AUTOSAR XML (schema 00050)
package /VectorAutosarExplorerGeneratedObjects/SYSTEM
  system System
package /VectorAutosarExplorerGeneratedObjects/DriveTrain
  can cluster DriveTrain: baudrate=500000, protocol-name=CAN, speed=250000
    can physical channel CANChannel: comm-connectors=[Connector_HeadUnit_ECU_95c543f36301506f, Connector_Battery_ECU_9b296f217afdec45]
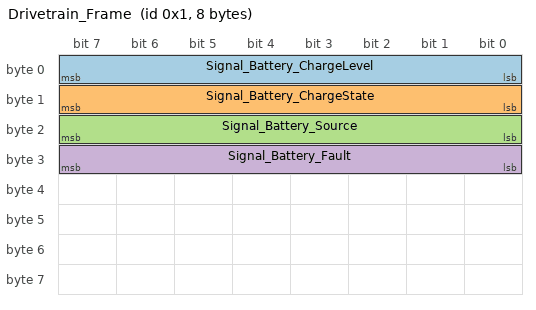
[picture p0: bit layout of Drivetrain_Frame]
      frame Drivetrain_Frame: id 0x1, from Battery_ECU, to HeadUnit_ECU, frame-length=8, can-addressing-mode=STANDARD, can-frame-tx-behavior=CAN-20
        pdu Drivetrain_Frame_PDU: length=8, transmission-mode-true-timing=cyclic-timing=time-period=1
          signal Signal_Battery_ChargeLevel: start 0, 8 bit, little-endian, system signal Signal_Battery_ChargeLevel_a9a9e6bb3df09836, data-type-policy=OVERRIDE, base-type=Temperature_BaseType, compu {phys=raw for raw 0..100; unit %}, to HeadUnit_ECU
          signal Signal_Battery_ChargeState: start 8, 8 bit, little-endian, system signal Signal_Battery_ChargeState_f9e63a8c0f39a04e, data-type-policy=OVERRIDE, base-type=Temperature_BaseType, compu {1=Charging, 2=Discharching (Discharging)}, to HeadUnit_ECU
          signal Signal_Battery_Source: start 16, 8 bit, little-endian, system signal Signal_Battery_Source_ac1e62a0b9f55c34, data-type-policy=OVERRIDE, base-type=Temperature_BaseType, compu {1=Power Source Available (Plugged), 2=Power Source Unavailable (Unplugged)}, transfer-property=TRIGGERED-ON-CHANGE, to HeadUnit_ECU
          signal Signal_Battery_Fault: start 24, 8 bit, little-endian, system signal Signal_Battery_Fault_d01f21cc3fdfd642, data-type-policy=OVERRIDE, base-type=Temperature_BaseType, compu {1=Faulty, 0=NormalOperation}, transfer-property=TRIGGERED-ON-CHANGE, to HeadUnit_ECU
package /VectorAutosarExplorerGeneratedObjects/Comfort
  can cluster Comfort: baudrate=500000, protocol-name=CAN, speed=250000
    can physical channel CANChannel
      comm-connectors:
        Connector_HeadUnit_ECU_2c2a28c65677685b
        Connector_Fan_ECU_fbc5880ce1a0cdea
        Connector_HeatPump_ECU_3a9462d6cf84e8d4
        Connector_Seat_ECU_c42df0ed14de8bdb
        Connector_SteeringWheel_ECU_2a26ad9393d8e118
        Comfort_Connector_Tester_65957222c6148118
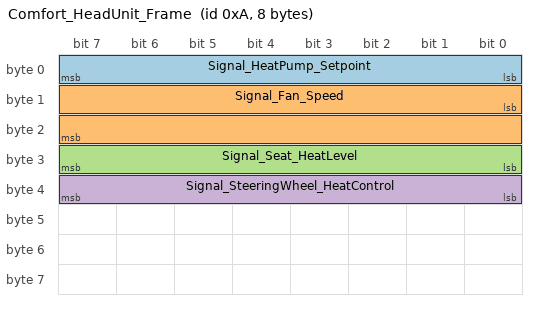
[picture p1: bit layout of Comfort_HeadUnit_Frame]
      frame Comfort_HeadUnit_Frame: id 0xA, from HeadUnit_ECU, to HeatPump_ECU Fan_ECU Seat_ECU SteeringWheel_ECU, frame-length=8, can-addressing-mode=STANDARD, can-frame-tx-behavior=CAN-20
        pdu Comfort_HeadUnit_Frame_PDU: length=8, transmission-mode-true-timing=cyclic-timing=time-period=0.1
          signal Signal_HeatPump_Setpoint: start 0, 8 bit, little-endian, system signal Signal_HeatPump_Setpoint_128f28339b77454b, data-type-policy=OVERRIDE, base-type=Temperature_BaseType, compu {phys=raw for raw 10..30; unit °C}, to HeatPump_ECU
          signal Signal_Fan_Speed: start 8, 16 bit, little-endian, system signal Signal_Fan_Setpoint_7226b1dfc825beac, data-type-policy=OVERRIDE, base-type=Speed_BaseType, compu {phys=raw for raw 0..3500; unit RPM}, to Fan_ECU
          signal Signal_Seat_HeatLevel: start 24, 8 bit, little-endian, system signal Signal_Seat_HeatLevel_70084504bb35d07f, data-type-policy=OVERRIDE, base-type=Temperature_BaseType, compu {0=Off, 1=Minimum (Low), 2=Medium, 3=Maximum (High)}, to Seat_ECU
          signal Signal_SteeringWheel_HeatControl: start 32, 8 bit, little-endian, system signal Signal_SteeringWheel_HeatControl_7a6769d229411a8c, data-type-policy=OVERRIDE, base-type=Temperature_BaseType, compu {1=Enabled (On), 0=Disabled (Off)}, to SteeringWheel_ECU
      frame Comfort_Fan_Frame: id 0x2, from Fan_ECU, to HeadUnit_ECU, frame-length=8, can-addressing-mode=STANDARD, can-frame-tx-behavior=CAN-20
        pdu Comfort_Fan_Frame_PDU: length=8, transmission-mode-true-timing=cyclic-timing=time-period=1
          signal Signal_Fan_Fault: start 0, 8 bit, little-endian, system signal Signal_Fan_Fault_f777c54e31a89d5c, data-type-policy=OVERRIDE, base-type=Temperature_BaseType, compu {1=Faulty, 0=NormalOperation}, transfer-property=TRIGGERED-ON-CHANGE, to HeadUnit_ECU
      frame Comfort_HeatPump_Frame: id 0x3, from HeatPump_ECU, to HeadUnit_ECU, frame-length=8, can-addressing-mode=STANDARD, can-frame-tx-behavior=CAN-20
        pdu Comfort_HeatPump_Frame_PDU: length=8, transmission-mode-true-timing=cyclic-timing=time-period=1
          signal Signal_HeatPump_Fault: start 0, 8 bit, little-endian, system signal sensor_frame_PDU_Fault_e8b584cee026b39c, data-type-policy=OVERRIDE, base-type=Temperature_BaseType, compu {1=Faulty, 0=NormalOperation}, transfer-property=TRIGGERED-ON-CHANGE, to HeadUnit_ECU
      frame Comfort_Seat_Frame: id 0x4, from Seat_ECU, to HeadUnit_ECU, frame-length=8, can-addressing-mode=STANDARD, can-frame-tx-behavior=CAN-20
        pdu Comfort_Seat_Frame_PDU: length=8, transmission-mode-true-timing=cyclic-timing=time-period=1
          signal Signal_Seat_Fault: start 0, 8 bit, little-endian, system signal Signal_Seat_Fault_d87a6a4f000a1433, data-type-policy=OVERRIDE, base-type=Temperature_BaseType, compu {1=Faulty, 0=NormalOperation}, transfer-property=TRIGGERED-ON-CHANGE, to HeadUnit_ECU
      frame Comfort_SteeringWheel_Frame: id 0x5, from SteeringWheel_ECU, to HeadUnit_ECU, frame-length=8, can-addressing-mode=STANDARD, can-frame-tx-behavior=CAN-20
        pdu Comfort_SteeringWheel_Frame_PDU: length=8, transmission-mode-true-timing=cyclic-timing=time-period=1
          signal Signal_SteeringWheel_Fault: start 0, 8 bit, little-endian, system signal Signal_SteeringWheel_Fault_45f4044b22d5124b, data-type-policy=OVERRIDE, base-type=Temperature_BaseType, compu {1=Faulty, 0=NormalOperation}, transfer-property=TRIGGERED-ON-CHANGE, to HeadUnit_ECU
      frame Comfort_Fan_NM_Tx: id 0x6, from Fan_ECU, frame-length=8, can-addressing-mode=STANDARD, can-frame-tx-behavior=CAN-20
        nm pdu Comfort_Fan_NM_PDU_Tx: length=8
      frame Comfort_Fan_NM_Rx: id 0x7, to Fan_ECU, frame-length=8, can-addressing-mode=STANDARD, can-frame-tx-behavior=CAN-20
        nm pdu Comfort_Fan_NM_PDU_Rx: length=8
      frame Comfort_TP_Diag_Request_Fan_ECU_Frame: id 0x1, from Tester, to Fan_ECU, frame-length=8, can-addressing-mode=STANDARD, can-frame-tx-behavior=CAN-20
        n pdu Comfort_TP_Diag_Request_Fan_ECU_Frame_PDU: length=8
      frame Comfort_TP_Diag_Response_Fan_ECU_Frame: id 0x8, from Fan_ECU, to Tester, frame-length=8, can-addressing-mode=STANDARD, can-frame-tx-behavior=CAN-20
        n pdu Comfort_TP_Diag_Response_Fan_ECU_Frame_PDU: length=8
      frame Comfort_DrivingCycle_Frame: id 0x9, to Fan_ECU, frame-length=8, can-addressing-mode=STANDARD, can-frame-tx-behavior=CAN-20
        pdu Comfort_DrivingCycle_Frame_PDU: length=8
          signal Signal_DrivingCycle: start 0, 8 bit, little-endian, system signal Signal_Comfort_DrivingCycle_d5cecd98dc1c368d, data-type-policy=OVERRIDE, base-type=Temperature_BaseType, compu {1=Start Driving Cycle (START), 0=Stop Driving Cycle (STOP)}, to Fan_ECU
      pdu triggering PduTriggering_FanDiagnostic_Request: pdu=Diag_Request_Fan_ECU_PDU, from Tester, to Fan_ECU
      pdu triggering PduTriggering_FanDiagnostic_Response: pdu=Diag_Response_Fan_ECU_PDU, from Fan_ECU, to Tester
package /VectorAutosarExplorerGeneratedObjects/Sensor
  can cluster Sensor: baudrate=500000, protocol-name=CAN, speed=250000
    can physical channel CANChannel: comm-connectors=[Connector_HeadUnit_ECU_7edfc098aa499a1f, Connector_Temperature_ECU_ff83a1b796b60c23]
      frame Sensor_Frame: id 0x1, from Temperature_ECU, to HeadUnit_ECU, frame-length=8, can-addressing-mode=STANDARD, can-frame-tx-behavior=CAN-20
        pdu Sensor_Frame_PDU: length=8, transmission-mode-true-timing=cyclic-timing=time-period=1
          signal Signal_CabinTemperature: start 0, 16 bit, little-endian, system signal sensor_frame_PDU_cabin_temperature_1a5c77ee0ca4a46f, data-type-policy=OVERRIDE, base-type=Temperature_BaseType, compu {phys=raw for raw -40..60; unit °C}, to HeadUnit_ECU
          signal Signal_Temperature_Fault: start 16, 8 bit, little-endian, system signal Signal_Temperature_Fault_b5edf4a00ad6d21e, data-type-policy=OVERRIDE, base-type=Temperature_BaseType, compu {1=Faulty, 0=NormalOperation}, transfer-property=TRIGGERED-ON-CHANGE, to HeadUnit_ECU
package /VectorAutosarExplorerGeneratedObjects/Connectivity
  ethernet cluster Connectivity: baudrate=10000, protocol-name=Ethernet, speed=10000
    ethernet physical channel EthernetChannel
package /VectorAutosarExplorerGeneratedObjects/ECU_INSTANCES
  8 x ecu instance, all with diagnostic-address=0:
    HeadUnit_ECU: associated-com-i-pdu-group=[PduGroup_7ed6fd6b46634bb0beb177a31eea70fc_Rx, PduGroup_e735d51c77a6499d8e3cc79f4d4e2413_Tx, PduGroup_f62c523302674429bac9bfb0130d26fc_Rx, PduGroup_fd71a12ac19d4ae49c9233b7fb46d2f9_Rx, PduGroup_94389edad0fd4b8a9a18c979c4be438f_Tx, PduGroup_4ce335607f0d496d824a8776292cb9bf_Tx, PduGroup_6ddcf328d5b649758527cd63f95447f1_Rx, PduGroup_f38bd1aa0ac04d3c83cf530d8dceeb01_Rx, PduGroup_1a6f4d5845e544b2a2618a4ec03cec3a_Rx, PduGroup_6aa6133542e64a6993e7cf271455ba99_Rx]
      can communication controller Controller_HeadUnit_ECU_38f089fabd3fe33a
      can communication controller Controller_HeadUnit_ECU_d090e2ec2e5ba0f5
      can communication controller Controller_HeadUnit_ECU_2c9374718a66f7d6
      can communication connector Connector_HeadUnit_ECU_7edfc098aa499a1f: comm-controller=Controller_HeadUnit_ECU_38f089fabd3fe33a
      can communication connector Connector_HeadUnit_ECU_95c543f36301506f: comm-controller=Controller_HeadUnit_ECU_d090e2ec2e5ba0f5
      can communication connector Connector_HeadUnit_ECU_2c2a28c65677685b: comm-controller=Controller_HeadUnit_ECU_2c9374718a66f7d6
    Temperature_ECU: associated-com-i-pdu-group=[PduGroup_f1fac14bd40543b89fef4fe4f2a5efae_Tx, PduGroup_72dc03cea81b4739b31c05ed5cd3dbd1_Rx, PduGroup_d56cee014acb48fd82f5251fde9d38dc_Rx]
      can communication controller Controller_Temperature_ECU_c07110918c6fa523
      can communication connector Connector_Temperature_ECU_ff83a1b796b60c23: comm-controller=Controller_Temperature_ECU_c07110918c6fa523
    Fan_ECU: associated-com-i-pdu-group=[PduGroup_0d620c5c31e9468c805e953e49743e0a_Rx, PduGroup_74671e2bef9a450f9b76d8edb8306b91_Tx, PduGroup_e08cbf222c5049fa934c8feff94811d6_Rx]
      can communication controller Controller_Fan_ECU_02f7c8db915351a9
      can communication connector Connector_Fan_ECU_fbc5880ce1a0cdea: comm-controller=Controller_Fan_ECU_02f7c8db915351a9
    HeatPump_ECU: associated-com-i-pdu-group=[PduGroup_85109675ea1744ec878d089e9e27daeb_Rx, PduGroup_aeec232ed2c94b1f9cb83060efb244b8_Tx, PduGroup_badd9e89c27a4ca5bf1cd541e0911355_Tx]
      can communication controller Controller_HeatPump_ECU_511b8aff1d8ab9ce
      can communication connector Connector_HeatPump_ECU_3a9462d6cf84e8d4: comm-controller=Controller_HeatPump_ECU_511b8aff1d8ab9ce
    Battery_ECU: associated-com-i-pdu-group=PduGroup_84f51cd14e9f4df39ea52c404ed1930c_Tx
      can communication controller Controller_Battery_ECU_d5f5a1c3e9916f6f
      can communication connector Connector_Battery_ECU_9b296f217afdec45: comm-controller=Controller_Battery_ECU_d5f5a1c3e9916f6f
    Seat_ECU: associated-com-i-pdu-group=[PduGroup_2de79ea012144cd4aaae25289b333147_Rx, PduGroup_826be7e94b564520a3be0f0a76d20cf9_Tx]
      can communication controller Controller_Seat_ECU_a599828f2f43056c
      can communication connector Connector_Seat_ECU_c42df0ed14de8bdb: comm-controller=Controller_Seat_ECU_a599828f2f43056c
    SteeringWheel_ECU: associated-com-i-pdu-group=[PduGroup_1bafec2f6a95418db185ce34df61c2b4_Tx, PduGroup_75ab3e447b944499944c8810ef270575_Rx]
      can communication controller Controller_SteeringWheel_ECU_ec927a5274a09bef
      can communication connector Connector_SteeringWheel_ECU_2a26ad9393d8e118: comm-controller=Controller_SteeringWheel_ECU_ec927a5274a09bef
    Tester
      can communication controller Comfort_Controller_Tester_63917ede39f0dcdd
      can communication connector Comfort_Connector_Tester_65957222c6148118: comm-controller=Comfort_Controller_Tester_63917ede39f0dcdd
package /VectorAutosarExplorerGeneratedObjects/FRAME
  can frame Sensor_Frame_HeadUnit: frame-length=8
    pdu to frame mapping PduToFrameMapping_17e5351f42ef30f2: packing-byte-order=little-endian, pdu=Sensor_Frame_HeadUnit_PDU, start-position=0
  can frame TP_Diag_Request_Fan_ECU_Frame: frame-length=8
    pdu to frame mapping PduToFrameMapping_f681b6d905256016: packing-byte-order=little-endian, pdu=TP_Diag_Request_Fan_ECU_Frame_PDU, start-position=0
  can frame TP_Diag_Response_Fan_ECU_Frame: frame-length=8
    pdu to frame mapping PduToFrameMapping_03f781b82e415c0c: packing-byte-order=little-endian, pdu=TP_Diag_Response_Fan_ECU_Frame_PDU, start-position=0
package /VectorAutosarExplorerGeneratedObjects/PDUS
  pdu Sensor_Frame_HeadUnit_PDU: length=8, transmission-mode-true-timing=cyclic-timing=time-period=0.1
    signal Signal_Temperature_Control: start 0, 8 bit, little-endian, system signal Signal_Temperature_Control_f6ab6982901901c1, data-type-policy=OVERRIDE, base-type=Temperature_BaseType, compu {1=Enabled (On), 0=Disabled (Off)}, to Temperature_ECU
  dcm i pdu Diag_Request_Fan_ECU_PDU: length=8, diag-pdu-type=DIAG-REQUEST
  dcm i pdu Diag_Response_Fan_ECU_PDU: length=8, diag-pdu-type=DIAG-RESPONSE
package /VectorAutosarExplorerGeneratedObjects/BASE_TYPES
  base type Temperature_BaseType: base-type-size=16, base-type-encoding=2C
  base type Speed_BaseType: base-type-size=16, base-type-encoding=NONE
  base type Boolean_BaseType: base-type-encoding=BOOLEAN
package /VectorAutosarExplorerGeneratedObjects/PDU_GROUP
  24 x i signal i pdu group:
    PduGroup_f1fac14bd40543b89fef4fe4f2a5efae_Tx: communication-direction=OUT
    PduGroup_7ed6fd6b46634bb0beb177a31eea70fc_Rx: communication-direction=IN
    PduGroup_e735d51c77a6499d8e3cc79f4d4e2413_Tx: communication-direction=OUT
    PduGroup_85109675ea1744ec878d089e9e27daeb_Rx: communication-direction=IN
    PduGroup_0d620c5c31e9468c805e953e49743e0a_Rx: communication-direction=IN
    PduGroup_74671e2bef9a450f9b76d8edb8306b91_Tx: communication-direction=OUT
    PduGroup_aeec232ed2c94b1f9cb83060efb244b8_Tx: communication-direction=OUT
    PduGroup_f62c523302674429bac9bfb0130d26fc_Rx: communication-direction=IN
    PduGroup_84f51cd14e9f4df39ea52c404ed1930c_Tx: communication-direction=OUT
    PduGroup_fd71a12ac19d4ae49c9233b7fb46d2f9_Rx: communication-direction=IN
    PduGroup_94389edad0fd4b8a9a18c979c4be438f_Tx: communication-direction=OUT
    PduGroup_72dc03cea81b4739b31c05ed5cd3dbd1_Rx: communication-direction=IN
    PduGroup_4ce335607f0d496d824a8776292cb9bf_Tx: communication-direction=OUT
    PduGroup_d56cee014acb48fd82f5251fde9d38dc_Rx: communication-direction=IN
    PduGroup_6ddcf328d5b649758527cd63f95447f1_Rx: communication-direction=IN
    PduGroup_badd9e89c27a4ca5bf1cd541e0911355_Tx: communication-direction=OUT
    PduGroup_f38bd1aa0ac04d3c83cf530d8dceeb01_Rx: communication-direction=IN
    PduGroup_2de79ea012144cd4aaae25289b333147_Rx: communication-direction=IN
    PduGroup_826be7e94b564520a3be0f0a76d20cf9_Tx: communication-direction=OUT
    PduGroup_1a6f4d5845e544b2a2618a4ec03cec3a_Rx: communication-direction=IN
    PduGroup_1bafec2f6a95418db185ce34df61c2b4_Tx: communication-direction=OUT
    PduGroup_6aa6133542e64a6993e7cf271455ba99_Rx: communication-direction=IN
    PduGroup_75ab3e447b944499944c8810ef270575_Rx: communication-direction=IN
    PduGroup_e08cbf222c5049fa934c8feff94811d6_Rx: communication-direction=IN
package /VectorAutosarExplorerGeneratedObjects/UNIT
  unit Celsius: display-name=°C  # DegreeCelsius
  unit Percent: display-name=%
  unit RPM: display-name=RPM
